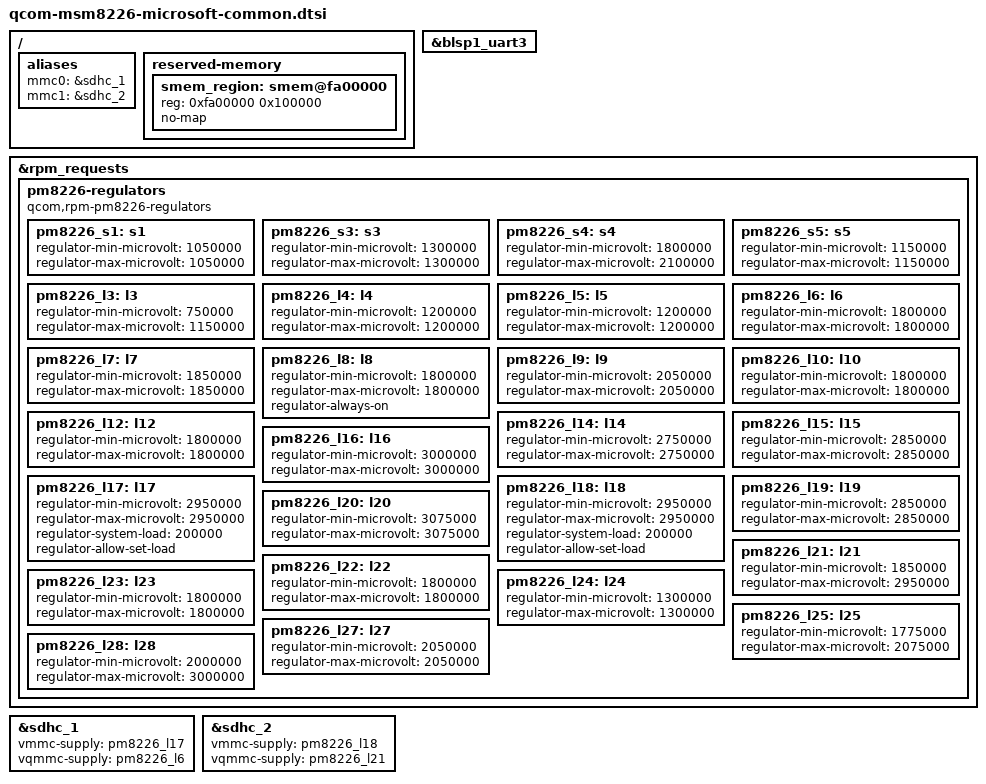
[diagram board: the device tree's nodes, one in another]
// SPDX-License-Identifier: BSD-3-Clause
/*
 * Common Board Device Tree for Microsoft MSM8226 Platforms
 *
 * Copyright (c) 2022, Jack Matthews <jm5112356@gmail.com>
 * Copyright (c) 2022, Ivaylo Ivanov <ivo.ivanov.ivanov1@gmail.com>
 * Copyright (c) 2022, Dominik Kobinski <dominikkobinski314@gmail.com>
 * Copyright (c) 2022, Rayyan Ansari <rayyan@ansari.sh>
 */

#include "qcom-msm8226.dtsi"
#include "qcom-pm8226.dtsi"

/*
 * Delete all generic (msm8226.dtsi) reserved
 * memory mappings which are different on these devices.
*/
/delete-node/ &smem_region;

/ {
	aliases {
		mmc0 = &sdhc_1; /* eMMC */
		mmc1 = &sdhc_2; /* microSD */
	};

	/*
	* This device being a WP platform has a different
	* memory layout than other Android based devices.
	* This smem memory region is directly copied from
	* the original UEFI firmware.
	*/
	reserved-memory {
		ranges;

		smem_region: smem@fa00000 {
			reg = <0xfa00000 0x100000>;
			no-map;
		};
	};
};

&blsp1_uart3 {
	status = "okay";
};

&rpm_requests {
	pm8226-regulators {
		compatible = "qcom,rpm-pm8226-regulators";

		/* These values were taken from the original firmware DSDT */
		pm8226_s1: s1 {
			regulator-min-microvolt = <1050000>;
			regulator-max-microvolt = <1050000>;
		};
		
		pm8226_s3: s3 {
			regulator-min-microvolt = <1300000>;
			regulator-max-microvolt = <1300000>;
		};
		
		pm8226_s4: s4 {
			regulator-min-microvolt = <1800000>;
			regulator-max-microvolt = <2100000>;
		};
		
		pm8226_s5: s5 {
			regulator-min-microvolt = <1150000>;
			regulator-max-microvolt = <1150000>;
		};
		
		pm8226_l3: l3 {
			regulator-min-microvolt = <750000>;
			regulator-max-microvolt = <1150000>;
		};
		
		pm8226_l4: l4 {
			regulator-min-microvolt = <1200000>;
			regulator-max-microvolt = <1200000>;
		};

		pm8226_l5: l5 {
			regulator-min-microvolt = <1200000>;
			regulator-max-microvolt = <1200000>;
		};
					
		pm8226_l6: l6 {
			regulator-min-microvolt = <1800000>;
			regulator-max-microvolt = <1800000>;
		};

		pm8226_l7: l7 {
			regulator-min-microvolt = <1850000>;
			regulator-max-microvolt = <1850000>;
		};
		
		pm8226_l8: l8 {
			regulator-min-microvolt = <1800000>;
			regulator-max-microvolt = <1800000>;
			regulator-always-on;
		};

		pm8226_l9: l9 {
			regulator-min-microvolt = <2050000>;
			regulator-max-microvolt = <2050000>;
		};
		
		pm8226_l10: l10 {
			regulator-min-microvolt = <1800000>;
			regulator-max-microvolt = <1800000>;
		};

		pm8226_l12: l12 {
			regulator-min-microvolt = <1800000>;
			regulator-max-microvolt = <1800000>;
		};

		pm8226_l14: l14 {
			regulator-min-microvolt = <2750000>;
			regulator-max-microvolt = <2750000>;
		};
		
		pm8226_l15: l15 {
			regulator-min-microvolt = <2850000>;
			regulator-max-microvolt = <2850000>;
		};
		
		pm8226_l16: l16 {
			regulator-min-microvolt = <3000000>;
			regulator-max-microvolt = <3000000>;
		};
					
		pm8226_l17: l17 {
			regulator-min-microvolt = <2950000>;
			regulator-max-microvolt = <2950000>;
			regulator-system-load = <200000>;
			regulator-allow-set-load;
		};
		
		pm8226_l18: l18 {
			regulator-min-microvolt = <2950000>;
			regulator-max-microvolt = <2950000>;
			regulator-system-load = <200000>;
			regulator-allow-set-load;
		};

		pm8226_l19: l19 {
			regulator-min-microvolt = <2850000>;
			regulator-max-microvolt = <2850000>;
		};
		
		pm8226_l20: l20 {
			regulator-min-microvolt = <3075000>;
			regulator-max-microvolt = <3075000>;
		};
		
		pm8226_l21: l21 {
			regulator-min-microvolt = <1850000>;
			regulator-max-microvolt = <2950000>;
		};
		
		pm8226_l22: l22 {
			regulator-min-microvolt = <1800000>;
			regulator-max-microvolt = <1800000>;
		};
		
		pm8226_l23: l23 {
			regulator-min-microvolt = <1800000>;
			regulator-max-microvolt = <1800000>;
		};

		pm8226_l24: l24 {
			regulator-min-microvolt = <1300000>;
			regulator-max-microvolt = <1300000>;
		};
		
		pm8226_l25: l25 {
			regulator-min-microvolt = <1775000>;
			regulator-max-microvolt = <2075000>;
		};
		
		pm8226_l27: l27 {
			regulator-min-microvolt = <2050000>;
			regulator-max-microvolt = <2050000>;
		};
		
		pm8226_l28: l28 {
			regulator-min-microvolt = <2000000>;
			regulator-max-microvolt = <3000000>;
		};
	};
};

&sdhc_1 {
	status = "okay";

	vmmc-supply = <&pm8226_l17>;
	vqmmc-supply = <&pm8226_l6>;
};

&sdhc_2 {
	status = "okay";
	
	vmmc-supply = <&pm8226_l18>;
	vqmmc-supply = <&pm8226_l21>;
};
